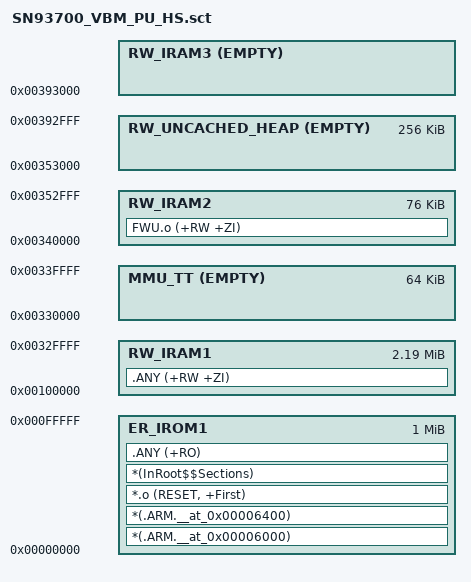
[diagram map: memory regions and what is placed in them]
; *************************************************************
; *** Scatter-Loading Description File generated by uVision ***
; *************************************************************

LR_IROM1 0x00000000 0x00100000  {    ; load region size_region
  ER_IROM1 0x00000000 0x00100000  {  ; load address = execution address
   *(.ARM.__at_0x00006000)
   *(.ARM.__at_0x00006400)
   *.o (RESET, +First)
   *(InRoot$$Sections)
   .ANY (+RO)
  }
  RW_IRAM1 0x00100000 0x00230000  {  ; RW data
   .ANY (+RW +ZI)
  }
  MMU_TT 0x00330000 EMPTY 0x00010000  {  ; RW data
  }
  RW_IRAM2 0x00340000 0x00013000  {  ; RW data
   FWU.o (+RW +ZI)
  }
  RW_UNCACHED_HEAP 0x00353000 EMPTY 0x00040000 {  ; RW data
  }
  RW_IRAM3 0x00393000 EMPTY 0x00000000	{  ; RW data
  }
}
